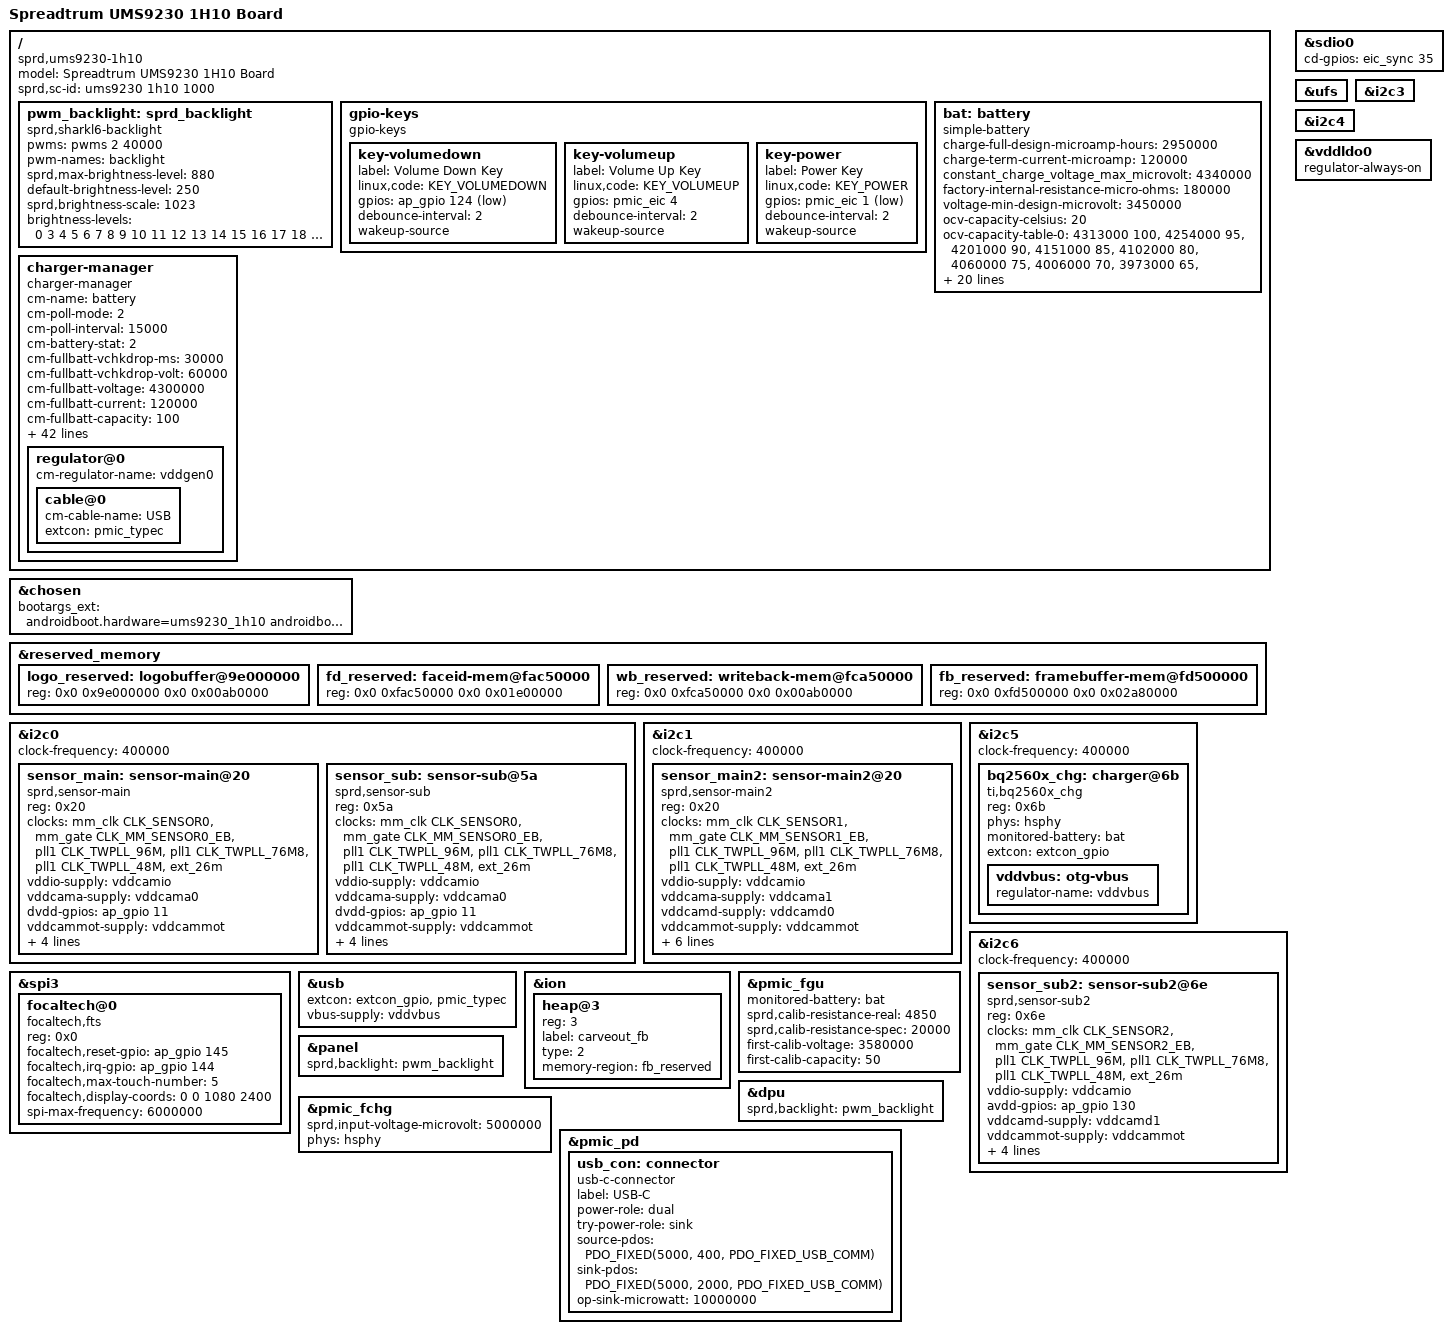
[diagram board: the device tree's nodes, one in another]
/dts-v1/;
/plugin/;
#include <dt-bindings/input/input.h>
#include <dt-bindings/gpio/gpio.h>
#include <dt-bindings/clock/sprd,ums9230-clk.h>
#include <dt-bindings/mfd/sprd,sc2730-regs.h>
#include <dt-bindings/mfd/sprd,sc2730-mask.h>
#include <dt-bindings/usb/pd.h>
#include "lcd/lcd_g40396_truly_mipi_fhd.dtsi"

/ {

	model = "Spreadtrum UMS9230 1H10 Board";

	compatible = "sprd,ums9230-1h10";

	sprd,sc-id = "ums9230 1h10 1000";
	fragment {
		target-path = "/";
		__overlay__ {
			pwm_backlight: sprd_backlight {
				compatible = "sprd,sharkl6-backlight";
				pwms = <&pwms 2 40000>;
				pwm-names = "backlight";
				sprd,max-brightness-level = <880>;
				default-brightness-level = <250>;
				sprd,brightness-scale = <1023>;
				brightness-levels = <
							  0   3   4   5   6   7
					  8   9  10  11  12  13  14  15  16  17
					 18  19  20  21  22  23  24  25  26  27
					 28  29  31  33  35  37  39  41  43  45
					 46  48  50  52  54  56  58  60  62  64
					 66  68  70  72  74  76  78  80  82  84
					 86  88  90  92  94  96  98 100 102 104
					106 108 110 112 114 116 118 120 122 124
					126 128 130 132 134 136 138 140 142 144
					146 148 150 152 154 156 158 160 162 164
					166 169 172 175 178 181 184 187 190 193
					196 199 202 205 208 211 214 217 220 223
					226 229 232 235 238 241 244 247 250 253
					256 259 262 265 268 271 274 277 280 283
					286 290 294 298 302 306 310 314 318 322
					326 330 334 338 342 346 350 354 358 362
					366 370 374 378 382 386 390 394 398 402
					406 410 414 418 422 426 430 434 438 442
					446 451 456 461 466 471 476 481 486 491
					496 501 506 511 516 521 526 531 536 541
					546 551 556 561 566 571 576 581 586 591
					596 601 606 611 616 621 626 631 636 641
					646 652 658 664 670 676 682 688 694 700
					706 712 718 724 730 736 742 748 754 760
					766 772 778 784 790 796 802 808 814 820
					826 832 838 844 850 856 862 868 874 880
				>;
			};

			gpio-keys {
				compatible = "gpio-keys";

				key-volumedown {
					label = "Volume Down Key";
					linux,code = <KEY_VOLUMEDOWN>;
					gpios = <&ap_gpio 124 GPIO_ACTIVE_LOW>;
					debounce-interval = <2>;
					wakeup-source;
				};

				key-volumeup {
					label = "Volume Up Key";
					linux,code = <KEY_VOLUMEUP>;
					gpios = <&pmic_eic 4 GPIO_ACTIVE_HIGH>;
					debounce-interval = <2>;
					wakeup-source;
				};

				key-power {
					label = "Power Key";
					linux,code = <KEY_POWER>;
					gpios = <&pmic_eic 1 GPIO_ACTIVE_LOW>;
					debounce-interval = <2>;
					wakeup-source;
				};
			};

			bat: battery {
				compatible = "simple-battery";
				charge-full-design-microamp-hours = <2950000>;
				charge-term-current-microamp = <120000>;
				constant_charge_voltage_max_microvolt = <4340000>;
				factory-internal-resistance-micro-ohms = <180000>;
				voltage-min-design-microvolt = <3450000>;
				ocv-capacity-celsius = <20>;
				ocv-capacity-table-0 = <4313000 100>, <4254000 95>, <4201000 90>,
							<4151000 85>, <4102000 80>, <4060000 75>,
							<4006000 70>, <3973000 65>, <3930000 60>,
							<3882000 55>, <3851000 50>, <3829000 45>,
							<3810000 40>, <3795000 35>, <3781000 30>,
							<3765000 25>, <3746000 20>, <3722000 15>,
							<3694000 10>, <3682000 5>, <3400000 0>;
				voltage-temp-table = <1095000 800>, <986000 850>, <878000 900>,
							  <775000 950>, <678000 1000>, <590000 1050>,
							  <510000 1100>, <440000 1150>, <378000 1200>,
							  <324000 1250>, <278000 1300>, <238000 1350>,
							  <204000 1400>, <175000 1450>, <150000 1500>,
							  <129000 1550>, <111000 1600>, <96000 1650>;
				capacity-temp-table = <45 100>, <25 100>, <10 98>, <0 93>, <(-10) 85>, <(-20) 64>;
				resistance-temp-table = <45 77>, <25 100>, <10 546>, <0 769>, <(-10) 892>, <(-20) 923>;
				charge-sdp-current-microamp = <500000 500000>;
				charge-dcp-current-microamp = <2000000 3000000>;
				charge-cdp-current-microamp = <1500000 1500000>;
				charge-unknown-current-microamp = <500000 500000>;
				charge-fchg-current-microamp = <3000000 2000000>;
			};

			charger-manager {
				compatible = "charger-manager";
				cm-name = "battery";
				cm-poll-mode = <2>;
				cm-poll-interval = <15000>;
				cm-battery-stat = <2>;

				cm-fullbatt-vchkdrop-ms = <30000>;
				cm-fullbatt-vchkdrop-volt = <60000>;
				cm-fullbatt-voltage = <4300000>;
				cm-fullbatt-current = <120000>;
				cm-fullbatt-capacity = <100>;

				cm-num-chargers = <1>;
				cm-num-fast-chargers = <1>;
				cm-chargers = "bq2560x_charger";
				cm-fast-chargers = "sc2730_fast_charger";
				cm-fuel-gauge = "sc27xx-fgu";

				/* in deci centigrade */
				cm-battery-cold = <200>;
				cm-battery-cold-in-minus;
				cm-battery-hot = <800>;
				cm-battery-temp-diff = <100>;

				/* Allow charging for 6hr */
				cm-charging-max = <21600000>;
				/* recovery charging after stop charging 45min */
				cm-discharging-max = <2700000>;

				/* the interval to feed charger watchdog */
				cm-wdt-interval = <60>;

				/* drop voltage in microVolts to allow shutdown */
				cm-shutdown-voltage = <3100000>;

				/* when 99% of the time is exceeded, it will be forced to 100% */
				cm-tickle-time-out = <1500>;

				/* how much time to allow capacity change */
				cm-one-cap-time = <30>;
				/* cm-thermal-zone = "board-thmzone"; */
				/* when the safe charging voltage is exceeded, stop charging */
				cm-charge-voltage-max = <6500000>;
				/* drop voltage in microVolts to restart charging */
				cm-charge-voltage-drop = <700000>;
				cm-dcp-jeita-temp-table = <1000 1030 0 4400000>, <1150 1180 700000 4400000>,
					<1450 1420 2000000 4400000>, <1600 1570 700000 4100000>;
				cm-sdp-jeita-temp-table = <1000 1030 0 4400000>, <1150 1180 500000 4400000>,
					<1450 1420 500000 4400000>, <1600 1570 500000 4100000>;
				cm-cdp-jeita-temp-table = <1000 1030 0 4400000>, <1150 1180 700000 4400000>,
					<1450 1420 1500000 4400000>, <1600 1570 700000 4100000>;
				cm-unknown-jeita-temp-table = <1000 1030 0 4400000>, <1150 1180 500000 4400000>,
					<1450 1420 500000 4400000>, <1600 1570 500000 4100000>;
				cm-fchg-jeita-temp-table = <1000 1030 0 4400000>, <1150 1180 700000 4400000>,
					<1450 1420 3000000 4400000>, <1600 1570 700000 4100000>;

				monitored-battery = <&bat>;
				cm-capacity-track;

				cm-cap-remap-table = <1 2 3>, <2 3 2>, <98 99 2>, <99 100 3>;

				regulator@0 {
					cm-regulator-name = "vddgen0";
					cable@0 {
						cm-cable-name = "USB";
						extcon = <&pmic_typec>;
					};
				};
			};
		};
	};
};

&chosen {
	bootargs_ext = "androidboot.hardware=ums9230_1h10 androidboot.dtbo_idx=0";
};

&reserved_memory {

	logo_reserved: logobuffer@9e000000{
		reg = <0x0 0x9e000000 0x0 0x00ab0000>;
	};

	fd_reserved: faceid-mem@fac50000 {
		reg = <0x0 0xfac50000 0x0 0x01e00000>;
	};

	wb_reserved: writeback-mem@fca50000 {
		reg = <0x0 0xfca50000 0x0 0x00ab0000>;
	};

	fb_reserved: framebuffer-mem@fd500000 {
		reg = <0x0 0xfd500000 0x0 0x02a80000>;
	};
};

&i2c0 {
	status = "okay";
	clock-frequency = <400000>;

	sensor_main: sensor-main@20 {
		compatible = "sprd,sensor-main";
		reg = <0x20>;
		clock-names = "clk_src","sensor_eb",
			"clk_96m","clk_76m8",
			"clk_48m","clk_26m";
		clocks = <&mm_clk CLK_SENSOR0>,<&mm_gate CLK_MM_SENSOR0_EB>,
				<&pll1 CLK_TWPLL_96M>,<&pll1 CLK_TWPLL_76M8>,
				<&pll1 CLK_TWPLL_48M>,<&ext_26m>;
		vddio-supply = <&vddcamio>;
		vddcama-supply = <&vddcama0>;
		dvdd-gpios = <&ap_gpio 11 0>;
		vddcammot-supply = <&vddcammot>;
		reset-gpios = <&ap_gpio 45 0>;
		power-down-gpios = <&ap_gpio 47 0>;
		sprd,phyid = <0>;
		csi = <&csi0>;
	};

	sensor_sub: sensor-sub@5a {
		compatible = "sprd,sensor-sub";
		reg = <0x5a>;
		clock-names = "clk_src","sensor_eb",
			"clk_96m","clk_76m8",
			"clk_48m","clk_26m";
		clocks = <&mm_clk CLK_SENSOR0>,<&mm_gate CLK_MM_SENSOR0_EB>,
				<&pll1 CLK_TWPLL_96M>,<&pll1 CLK_TWPLL_76M8>,
				<&pll1 CLK_TWPLL_48M>,<&ext_26m>;
		vddio-supply = <&vddcamio>;
		vddcama-supply = <&vddcama0>;
		dvdd-gpios = <&ap_gpio 11 0>;
		vddcammot-supply = <&vddcammot>;
		reset-gpios = <&ap_gpio 44 0>;
		power-down-gpios = <&ap_gpio 46 0>;
	/*	mipi-switch-en-gpios = <&ap_gpio 55 0>;*/
	/*	mipi-switch-mode-gpios = <&ap_gpio 8 0>;*/
		sprd,phyid = <2>;
		csi = <&csi0>;
	};
};

&i2c1 {
	status = "okay";
	clock-frequency = <400000>;

	sensor_main2: sensor-main2@20 {
		compatible = "sprd,sensor-main2";
		reg = <0x20>;
		clock-names = "clk_src","sensor_eb",
			"clk_96m","clk_76m8",
			"clk_48m","clk_26m";
		clocks = <&mm_clk CLK_SENSOR1>,<&mm_gate CLK_MM_SENSOR1_EB>,
				<&pll1 CLK_TWPLL_96M>,<&pll1 CLK_TWPLL_76M8>,
				<&pll1 CLK_TWPLL_48M>,<&ext_26m>;
		vddio-supply = <&vddcamio>;
		vddcama-supply = <&vddcama1>;
		vddcamd-supply = <&vddcamd0>;
		vddcammot-supply = <&vddcammot>;
		avdd-gpios = <&ap_gpio 33 0>;
		mot-gpios = <&ap_gpio 88 0>;
		reset-gpios = <&ap_gpio 41 0>;
		power-down-gpios = <&ap_gpio 40 0>;
	/*	mipi-switch-en-gpios = <&ap_gpio 55 0>;*/
	/*	mipi-switch-mode-gpios = <&ap_gpio 8 0>;*/
		sprd,phyid = <4>;
		csi = <&csi1>;
	};


};

&i2c5 {
	status = "okay";
	clock-frequency = <400000>;

	bq2560x_chg: charger@6b {
		compatible = "ti,bq2560x_chg";
		reg = <0x6b>;
		phys = <&hsphy>;
		monitored-battery = <&bat>;
		extcon = <&extcon_gpio>;
		vddvbus:otg-vbus {
			regulator-name = "vddvbus";
		};
	};
};

&i2c6 {
	status = "okay";
	clock-frequency = <400000>;

	sensor_sub2: sensor-sub2@6e {
		compatible = "sprd,sensor-sub2";
		reg = <0x6e>;
		clock-names = "clk_src","sensor_eb",
			"clk_96m","clk_76m8",
			"clk_48m","clk_26m";
		clocks = <&mm_clk CLK_SENSOR2>,<&mm_gate CLK_MM_SENSOR2_EB>,
			<&pll1 CLK_TWPLL_96M>,<&pll1 CLK_TWPLL_76M8>,
			<&pll1 CLK_TWPLL_48M>,<&ext_26m>;
		vddio-supply = <&vddcamio>;
		avdd-gpios = <&ap_gpio 130 0>;
		vddcamd-supply = <&vddcamd1>;
		vddcammot-supply = <&vddcammot>;
		mot-gpios = <&ap_gpio 112 0>;
		reset-gpios = <&ap_gpio 114 0>;
	/*	power-down-gpios = <&ap_gpio 40 0>;*/
		sprd,phyid = <3>;
		csi = <&csi2>;
	};
};

&spi3 {
	status = "okay";

	focaltech@0 {
		compatible = "focaltech,fts";
		reg = <0x0>;
		focaltech,reset-gpio = <&ap_gpio 145 GPIO_ACTIVE_HIGH>;
		focaltech,irq-gpio = <&ap_gpio 144 GPIO_ACTIVE_HIGH>;
		focaltech,max-touch-number = <5>;
		focaltech,display-coords =  <0 0 1080 2400>;
		spi-max-frequency = <6000000>;
	};
};

&usb {
	extcon = <&extcon_gpio>, <&pmic_typec>;
	vbus-supply = <&vddvbus>;
};

&sdio0 {
	cd-gpios = <&eic_sync 35 GPIO_ACTIVE_HIGH>;
};

&ion {
	heap@3 {
		reg = <3>;
		label = "carveout_fb";
		type = <2>;
		memory-region = <&fb_reserved>;
	};
};

&ufs {
	status = "okay";
};

&i2c3 {
	status = "okay";
};

&i2c4 {
	status = "okay";
};


&vddldo0 {
	regulator-always-on;
};

&pmic_fgu {
	monitored-battery = <&bat>;
	sprd,calib-resistance-real = <4850>;
	sprd,calib-resistance-spec = <20000>;
	first-calib-voltage = <3580000>;
	first-calib-capacity = <50>;
};

&panel {
	sprd,backlight = <&pwm_backlight>;
};

&dpu {
	sprd,backlight = <&pwm_backlight>;
};

&pmic_fchg {
	sprd,input-voltage-microvolt = <5000000>;
	phys = <&hsphy>;
};

&pmic_pd {
	status = "okay";
	usb_con: connector {
		compatible = "usb-c-connector";
		label = "USB-C";
		power-role = "dual";
		try-power-role = "sink";
		source-pdos = <PDO_FIXED(5000, 400, PDO_FIXED_USB_COMM)>;
		sink-pdos = <PDO_FIXED(5000, 2000, PDO_FIXED_USB_COMM)>;
		op-sink-microwatt = <10000000>;
	};
};
